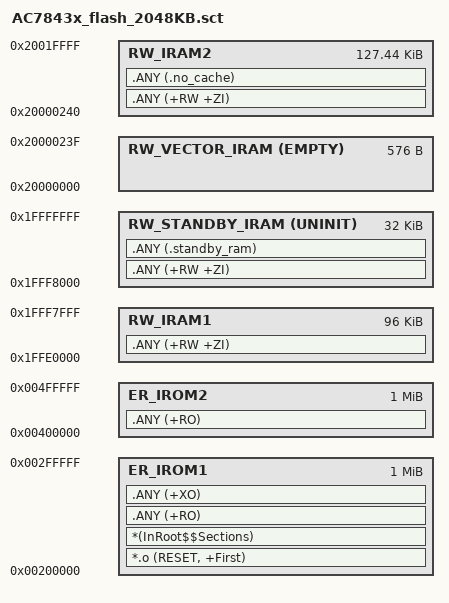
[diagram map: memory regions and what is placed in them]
; *************************************************************
; *** Scatter-Loading Description File generated by uVision ***
; *************************************************************

LR_IROM1 0x00200000 0x00100000  {    ; load region size_region
  ER_IROM1 0x00200000 0x00100000  {  ; load address = execution address
   *.o (RESET, +First)
   *(InRoot$$Sections)
   .ANY (+RO)
   .ANY (+XO)
  }

  RW_IRAM1 0x1FFE0000 0x00020000-0x8000  {  ; SRAM_L contain cache
   .ANY (+RW +ZI)
  }

  RW_STANDBY_IRAM 0x1FFF8000 UNINIT 0x8000  {  ; standby power mode retention RAM
   .ANY (+RW +ZI)
   .ANY (.standby_ram)
  }

  RW_VECTOR_IRAM 0x20000000 EMPTY 0x00000240  {  ; vector table used RAM

  }

  RW_IRAM2 0x20000240 0x00020000-0x240  {  ; SRAM_U no cache
   .ANY (+RW +ZI)
   .ANY (.no_cache)
  }
}

LR_IROM2 0x00400000 0x00100000  {    ; load region size_region
  ER_IROM2 0x00400000 0x00100000  {  ; load address = execution address
   .ANY (+RO)
  }
}
